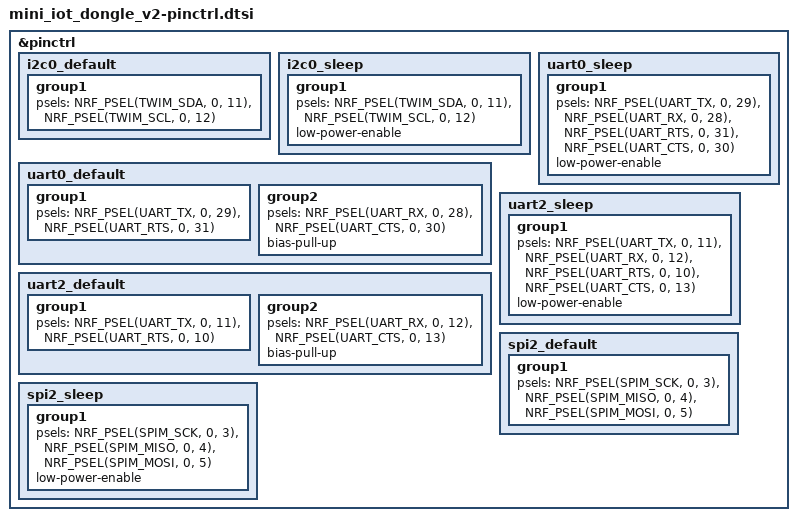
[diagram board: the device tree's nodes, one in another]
&pinctrl {


    i2c0_default: i2c0_default {
        group1 {
            psels = <NRF_PSEL(TWIM_SDA, 0, 11)>,
                    <NRF_PSEL(TWIM_SCL, 0, 12)>;
        };
    };

    i2c0_sleep: i2c0_sleep {
        group1 {
            psels = <NRF_PSEL(TWIM_SDA, 0, 11)>,
                    <NRF_PSEL(TWIM_SCL, 0, 12)>;
            low-power-enable;
        };
    };

    uart0_default: uart0_default {
        group1 {
            psels = <NRF_PSEL(UART_TX, 0, 29)>,
                    <NRF_PSEL(UART_RTS, 0, 31)>;
        };
        group2 {
            psels = <NRF_PSEL(UART_RX, 0, 28)>,
                    <NRF_PSEL(UART_CTS, 0, 30)>;
            bias-pull-up;
        };
    };
    uart0_sleep: uart0_sleep {
        group1 {
            psels = <NRF_PSEL(UART_TX, 0, 29)>,
                    <NRF_PSEL(UART_RX, 0, 28)>,
                    <NRF_PSEL(UART_RTS, 0, 31)>,
                    <NRF_PSEL(UART_CTS, 0, 30)>;
            low-power-enable;
        };
    };

    uart2_default: uart2_default {
        group1 {
            psels = <NRF_PSEL(UART_TX, 0, 11)>,
                    <NRF_PSEL(UART_RTS, 0, 10)>;
        };
        group2 {
            psels = <NRF_PSEL(UART_RX, 0, 12)>,
                    <NRF_PSEL(UART_CTS, 0, 13)>;
            bias-pull-up;
        };
    };
    uart2_sleep: uart2_sleep {
        group1 {
            psels = <NRF_PSEL(UART_TX, 0, 11)>,
                    <NRF_PSEL(UART_RX, 0, 12)>,
                    <NRF_PSEL(UART_RTS, 0, 10)>,
                    <NRF_PSEL(UART_CTS, 0, 13)>;
            low-power-enable;
        };
    };

    spi2_default: spi2_default {
        group1 {
            psels = <NRF_PSEL(SPIM_SCK, 0, 3)>,
                    <NRF_PSEL(SPIM_MISO, 0, 4)>,
                    <NRF_PSEL(SPIM_MOSI, 0, 5)>;
        };
    };

    spi2_sleep: spi2_sleep {
        group1 {
            psels = <NRF_PSEL(SPIM_SCK, 0, 3)>,
                    <NRF_PSEL(SPIM_MISO, 0, 4)>,
                    <NRF_PSEL(SPIM_MOSI, 0, 5)>;
            low-power-enable;
        };
    };


};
